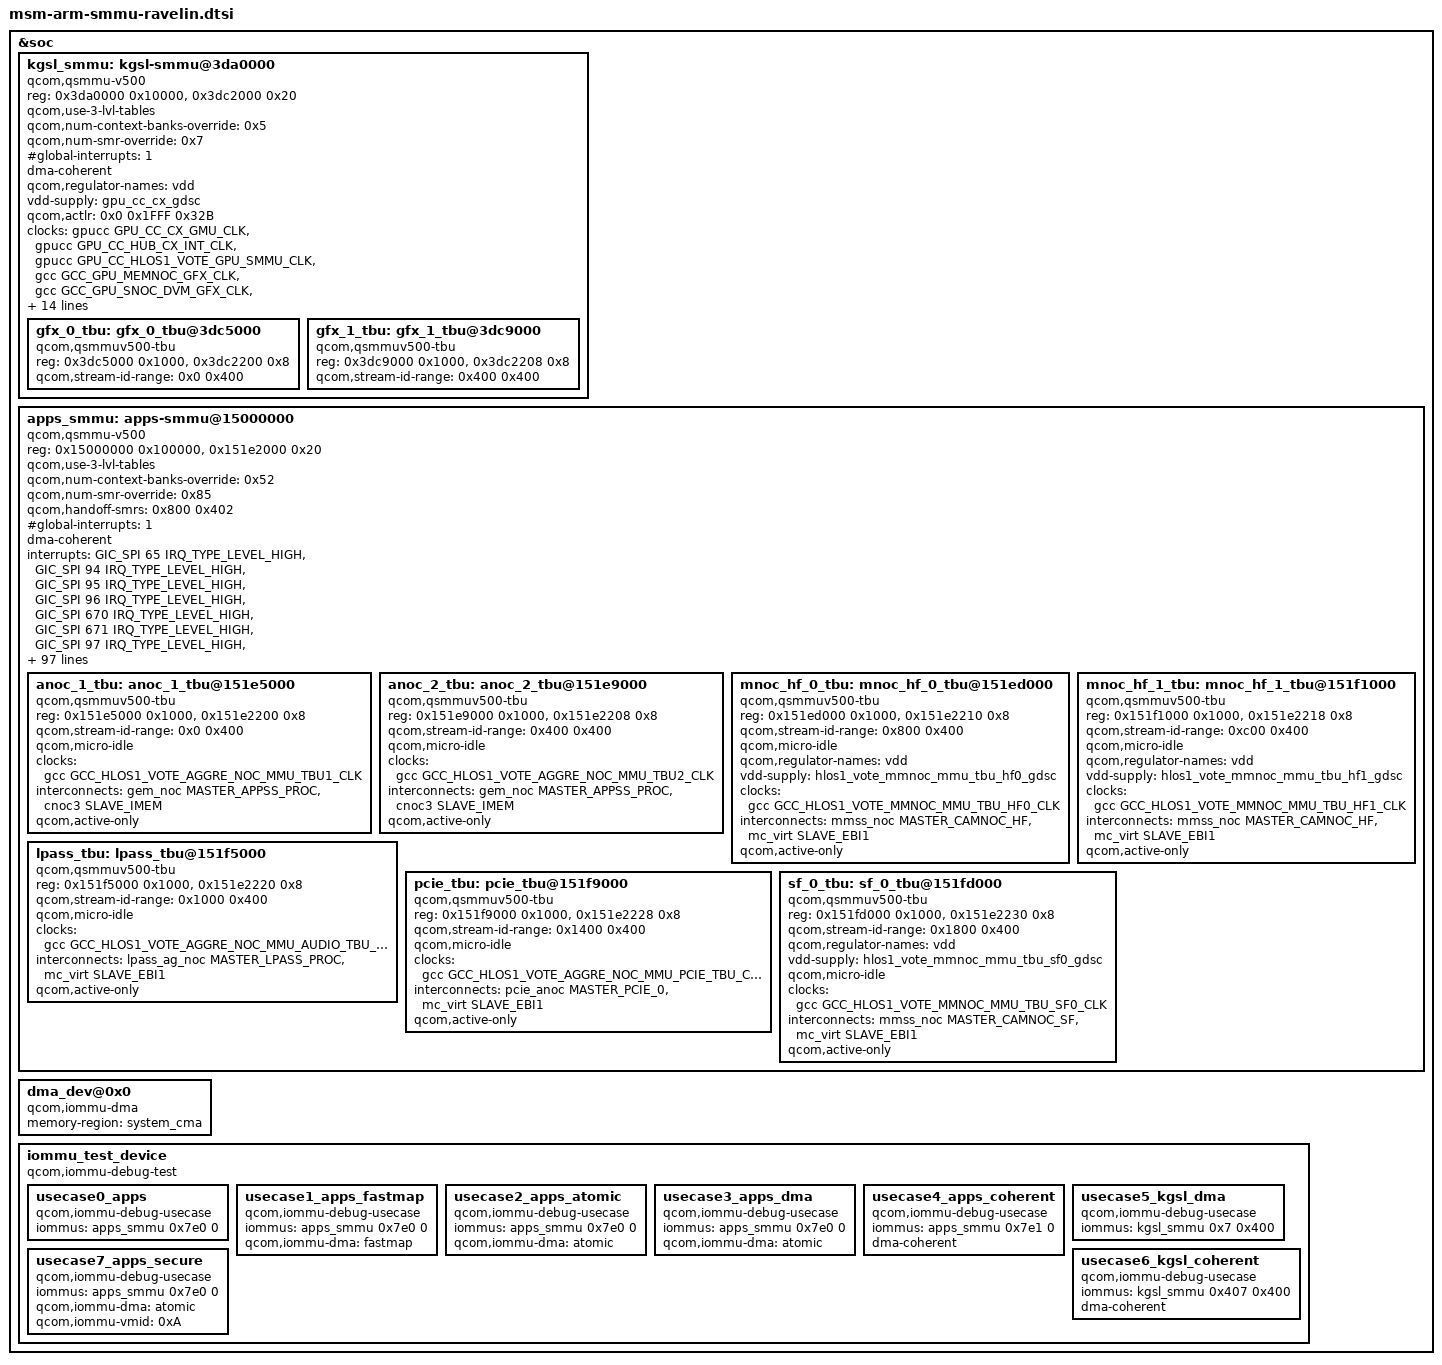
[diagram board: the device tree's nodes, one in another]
#include <dt-bindings/interrupt-controller/arm-gic.h>

&soc {
	kgsl_smmu: kgsl-smmu@3da0000 {
		compatible = "qcom,qsmmu-v500", "qcom,adreno-smmu";
		reg = <0x3da0000 0x10000>,
			<0x3dc2000 0x20>;
		reg-names = "base", "tcu-base";
		#iommu-cells = <2>;
		qcom,use-3-lvl-tables;
		qcom,num-context-banks-override = <0x5>;
		qcom,num-smr-override = <0x7>;
		#global-interrupts = <1>;
		#size-cells = <1>;
		#address-cells = <1>;
		ranges;
		dma-coherent;

		qcom,regulator-names = "vdd";
		vdd-supply = <&gpu_cc_cx_gdsc>;

		qcom,actlr =
			/* All CBs of GFX: +15 deep PF */
			<0x0 0x1FFF 0x32B>;

		clocks = <&gpucc GPU_CC_CX_GMU_CLK>,
			<&gpucc GPU_CC_HUB_CX_INT_CLK>,
			<&gpucc GPU_CC_HLOS1_VOTE_GPU_SMMU_CLK>,
			<&gcc GCC_GPU_MEMNOC_GFX_CLK>,
			<&gcc GCC_GPU_SNOC_DVM_GFX_CLK>,
			<&gpucc GPU_CC_AHB_CLK>;
		clock-names =
			"gpu_cc_cx_gmu",
			"gpu_cc_hub_cx_int",
			"gpu_cc_hlos1_vote_gpu_smmu",
			"gcc_gpu_memnoc_gfx",
			"gcc_gpu_snoc_dvm_gfx",
			"gpu_cc_ahb";

		interrupts =	<GIC_SPI 674 IRQ_TYPE_LEVEL_HIGH>,
				<GIC_SPI 678 IRQ_TYPE_LEVEL_HIGH>,
				<GIC_SPI 679 IRQ_TYPE_LEVEL_HIGH>,
				<GIC_SPI 680 IRQ_TYPE_LEVEL_HIGH>,
				<GIC_SPI 681 IRQ_TYPE_LEVEL_HIGH>,
				<GIC_SPI 682 IRQ_TYPE_LEVEL_HIGH>,
				<GIC_SPI 683 IRQ_TYPE_LEVEL_HIGH>,
				<GIC_SPI 684 IRQ_TYPE_LEVEL_HIGH>,
				<GIC_SPI 685 IRQ_TYPE_LEVEL_HIGH>,
				<GIC_SPI 686 IRQ_TYPE_LEVEL_HIGH>,
				<GIC_SPI 687 IRQ_TYPE_LEVEL_HIGH>,
				<GIC_SPI 688 IRQ_TYPE_LEVEL_HIGH>,
				<GIC_SPI 422 IRQ_TYPE_LEVEL_HIGH>;

		gfx_0_tbu: gfx_0_tbu@3dc5000 {
			compatible = "qcom,qsmmuv500-tbu";
			reg = <0x3dc5000 0x1000>,
				<0x3dc2200 0x8>;
			reg-names = "base", "status-reg";
			qcom,stream-id-range = <0x0 0x400>;
		};

		gfx_1_tbu: gfx_1_tbu@3dc9000 {
			compatible = "qcom,qsmmuv500-tbu";
			reg = <0x3dc9000 0x1000>,
				<0x3dc2208 0x8>;
			reg-names = "base", "status-reg";
			qcom,stream-id-range = <0x400 0x400>;
		};
	};

	apps_smmu: apps-smmu@15000000 {
		compatible = "qcom,qsmmu-v500";
		reg = <0x15000000 0x100000>,
			<0x151e2000 0x20>;
		reg-names = "base", "tcu-base";
		#iommu-cells = <2>;
		qcom,use-3-lvl-tables;
		qcom,num-context-banks-override = <0x52>;
		qcom,num-smr-override = <0x85>;
		qcom,handoff-smrs = <0x800 0x402>;
		#global-interrupts = <1>;
		#size-cells = <1>;
		#address-cells = <1>;
		ranges;
		dma-coherent;

		interrupts =	<GIC_SPI 65 IRQ_TYPE_LEVEL_HIGH>,
				<GIC_SPI 94 IRQ_TYPE_LEVEL_HIGH>,
				<GIC_SPI 95 IRQ_TYPE_LEVEL_HIGH>,
				<GIC_SPI 96 IRQ_TYPE_LEVEL_HIGH>,
				<GIC_SPI 670 IRQ_TYPE_LEVEL_HIGH>,
				<GIC_SPI 671 IRQ_TYPE_LEVEL_HIGH>,
				<GIC_SPI 97 IRQ_TYPE_LEVEL_HIGH>,
				<GIC_SPI 98 IRQ_TYPE_LEVEL_HIGH>,
				<GIC_SPI 99 IRQ_TYPE_LEVEL_HIGH>,
				<GIC_SPI 100 IRQ_TYPE_LEVEL_HIGH>,
				<GIC_SPI 101 IRQ_TYPE_LEVEL_HIGH>,
				<GIC_SPI 102 IRQ_TYPE_LEVEL_HIGH>,
				<GIC_SPI 103 IRQ_TYPE_LEVEL_HIGH>,
				<GIC_SPI 104 IRQ_TYPE_LEVEL_HIGH>,
				<GIC_SPI 105 IRQ_TYPE_LEVEL_HIGH>,
				<GIC_SPI 106 IRQ_TYPE_LEVEL_HIGH>,
				<GIC_SPI 107 IRQ_TYPE_LEVEL_HIGH>,
				<GIC_SPI 108 IRQ_TYPE_LEVEL_HIGH>,
				<GIC_SPI 109 IRQ_TYPE_LEVEL_HIGH>,
				<GIC_SPI 110 IRQ_TYPE_LEVEL_HIGH>,
				<GIC_SPI 111 IRQ_TYPE_LEVEL_HIGH>,
				<GIC_SPI 112 IRQ_TYPE_LEVEL_HIGH>,
				<GIC_SPI 113 IRQ_TYPE_LEVEL_HIGH>,
				<GIC_SPI 114 IRQ_TYPE_LEVEL_HIGH>,
				<GIC_SPI 115 IRQ_TYPE_LEVEL_HIGH>,
				<GIC_SPI 116 IRQ_TYPE_LEVEL_HIGH>,
				<GIC_SPI 117 IRQ_TYPE_LEVEL_HIGH>,
				<GIC_SPI 118 IRQ_TYPE_LEVEL_HIGH>,
				<GIC_SPI 181 IRQ_TYPE_LEVEL_HIGH>,
				<GIC_SPI 182 IRQ_TYPE_LEVEL_HIGH>,
				<GIC_SPI 183 IRQ_TYPE_LEVEL_HIGH>,
				<GIC_SPI 184 IRQ_TYPE_LEVEL_HIGH>,
				<GIC_SPI 185 IRQ_TYPE_LEVEL_HIGH>,
				<GIC_SPI 186 IRQ_TYPE_LEVEL_HIGH>,
				<GIC_SPI 187 IRQ_TYPE_LEVEL_HIGH>,
				<GIC_SPI 188 IRQ_TYPE_LEVEL_HIGH>,
				<GIC_SPI 189 IRQ_TYPE_LEVEL_HIGH>,
				<GIC_SPI 190 IRQ_TYPE_LEVEL_HIGH>,
				<GIC_SPI 191 IRQ_TYPE_LEVEL_HIGH>,
				<GIC_SPI 192 IRQ_TYPE_LEVEL_HIGH>,
				<GIC_SPI 315 IRQ_TYPE_LEVEL_HIGH>,
				<GIC_SPI 316 IRQ_TYPE_LEVEL_HIGH>,
				<GIC_SPI 317 IRQ_TYPE_LEVEL_HIGH>,
				<GIC_SPI 318 IRQ_TYPE_LEVEL_HIGH>,
				<GIC_SPI 319 IRQ_TYPE_LEVEL_HIGH>,
				<GIC_SPI 320 IRQ_TYPE_LEVEL_HIGH>,
				<GIC_SPI 321 IRQ_TYPE_LEVEL_HIGH>,
				<GIC_SPI 322 IRQ_TYPE_LEVEL_HIGH>,
				<GIC_SPI 323 IRQ_TYPE_LEVEL_HIGH>,
				<GIC_SPI 324 IRQ_TYPE_LEVEL_HIGH>,
				<GIC_SPI 325 IRQ_TYPE_LEVEL_HIGH>,
				<GIC_SPI 326 IRQ_TYPE_LEVEL_HIGH>,
				<GIC_SPI 327 IRQ_TYPE_LEVEL_HIGH>,
				<GIC_SPI 328 IRQ_TYPE_LEVEL_HIGH>,
				<GIC_SPI 329 IRQ_TYPE_LEVEL_HIGH>,
				<GIC_SPI 330 IRQ_TYPE_LEVEL_HIGH>,
				<GIC_SPI 331 IRQ_TYPE_LEVEL_HIGH>,
				<GIC_SPI 332 IRQ_TYPE_LEVEL_HIGH>,
				<GIC_SPI 333 IRQ_TYPE_LEVEL_HIGH>,
				<GIC_SPI 334 IRQ_TYPE_LEVEL_HIGH>,
				<GIC_SPI 335 IRQ_TYPE_LEVEL_HIGH>,
				<GIC_SPI 336 IRQ_TYPE_LEVEL_HIGH>,
				<GIC_SPI 337 IRQ_TYPE_LEVEL_HIGH>,
				<GIC_SPI 338 IRQ_TYPE_LEVEL_HIGH>,
				<GIC_SPI 339 IRQ_TYPE_LEVEL_HIGH>,
				<GIC_SPI 340 IRQ_TYPE_LEVEL_HIGH>,
				<GIC_SPI 341 IRQ_TYPE_LEVEL_HIGH>,
				<GIC_SPI 342 IRQ_TYPE_LEVEL_HIGH>,
				<GIC_SPI 343 IRQ_TYPE_LEVEL_HIGH>,
				<GIC_SPI 344 IRQ_TYPE_LEVEL_HIGH>,
				<GIC_SPI 345 IRQ_TYPE_LEVEL_HIGH>,
				<GIC_SPI 395 IRQ_TYPE_LEVEL_HIGH>,
				<GIC_SPI 396 IRQ_TYPE_LEVEL_HIGH>,
				<GIC_SPI 397 IRQ_TYPE_LEVEL_HIGH>,
				<GIC_SPI 398 IRQ_TYPE_LEVEL_HIGH>,
				<GIC_SPI 399 IRQ_TYPE_LEVEL_HIGH>,
				<GIC_SPI 400 IRQ_TYPE_LEVEL_HIGH>,
				<GIC_SPI 401 IRQ_TYPE_LEVEL_HIGH>,
				<GIC_SPI 402 IRQ_TYPE_LEVEL_HIGH>,
				<GIC_SPI 403 IRQ_TYPE_LEVEL_HIGH>,
				<GIC_SPI 404 IRQ_TYPE_LEVEL_HIGH>,
				<GIC_SPI 405 IRQ_TYPE_LEVEL_HIGH>,
				<GIC_SPI 406 IRQ_TYPE_LEVEL_HIGH>,
				<GIC_SPI 407 IRQ_TYPE_LEVEL_HIGH>,
				<GIC_SPI 408 IRQ_TYPE_LEVEL_HIGH>,
				<GIC_SPI 409 IRQ_TYPE_LEVEL_HIGH>,
				<GIC_SPI 418 IRQ_TYPE_LEVEL_HIGH>,
				<GIC_SPI 419 IRQ_TYPE_LEVEL_HIGH>,
				<GIC_SPI 412 IRQ_TYPE_LEVEL_HIGH>,
				<GIC_SPI 421 IRQ_TYPE_LEVEL_HIGH>,
				<GIC_SPI 707 IRQ_TYPE_LEVEL_HIGH>,
				<GIC_SPI 423 IRQ_TYPE_LEVEL_HIGH>,
				<GIC_SPI 424 IRQ_TYPE_LEVEL_HIGH>,
				<GIC_SPI 425 IRQ_TYPE_LEVEL_HIGH>,
				<GIC_SPI 690 IRQ_TYPE_LEVEL_HIGH>,
				<GIC_SPI 691 IRQ_TYPE_LEVEL_HIGH>,
				<GIC_SPI 692 IRQ_TYPE_LEVEL_HIGH>;

		qcom,actlr =
			/* For video clients, +3 PF */
			<0x1980 0x3F 0x103>,
			/* Display and camera clients, +0 PF */
			<0x1900 0x3F 0x1>,
			<0x1800 0xFF 0x1>,
			<0x800 0x7FF 0x1>;

		clocks = <&gcc GCC_HLOS1_VOTE_MMU_TCU_CLK>;
		clock-names =
			"gcc_hlos1_vote_mmu_tcu_clk";
		interconnects = <&gem_noc MASTER_APPSS_PROC
				&cnoc3 SLAVE_TCU>;
		qcom,active-only;

		anoc_1_tbu: anoc_1_tbu@151e5000 {
			compatible = "qcom,qsmmuv500-tbu";
			reg = <0x151e5000 0x1000>,
				<0x151e2200 0x8>;
			reg-names = "base", "status-reg";
			qcom,stream-id-range = <0x0 0x400>;
			qcom,micro-idle;
			clocks = <&gcc GCC_HLOS1_VOTE_AGGRE_NOC_MMU_TBU1_CLK>;
			clock-names =
				"gcc_hlos1_vote_aggre_noc_mmu_tbu1_clk";
			interconnects = <&gem_noc MASTER_APPSS_PROC
					&cnoc3 SLAVE_IMEM>;
			qcom,active-only;
		};

		anoc_2_tbu: anoc_2_tbu@151e9000 {
			compatible = "qcom,qsmmuv500-tbu";
			reg = <0x151e9000 0x1000>,
				<0x151e2208  0x8>;
			reg-names = "base", "status-reg";
			qcom,stream-id-range = <0x400 0x400>;
			qcom,micro-idle;
			clocks = <&gcc GCC_HLOS1_VOTE_AGGRE_NOC_MMU_TBU2_CLK>;
			clock-names =
				"gcc_hlos1_vote_aggre_noc_mmu_tbu2_clk";
			interconnects = <&gem_noc MASTER_APPSS_PROC
					&cnoc3 SLAVE_IMEM>;
			qcom,active-only;
		};

		mnoc_hf_0_tbu: mnoc_hf_0_tbu@151ed000 {
			compatible = "qcom,qsmmuv500-tbu";
			reg = <0x151ed000 0x1000>,
				<0x151e2210  0x8>;
			reg-names = "base", "status-reg";
			qcom,stream-id-range = <0x800 0x400>;
			qcom,micro-idle;
			qcom,regulator-names = "vdd";
			vdd-supply = <&hlos1_vote_mmnoc_mmu_tbu_hf0_gdsc>;
			clocks = <&gcc GCC_HLOS1_VOTE_MMNOC_MMU_TBU_HF0_CLK>;
			clock-names =
				"gcc_hlos1_vote_mmnoc_mmu_tbu_hf0_clk";
			interconnects = <&mmss_noc MASTER_CAMNOC_HF
					&mc_virt SLAVE_EBI1>;
			qcom,active-only;
		};

		mnoc_hf_1_tbu: mnoc_hf_1_tbu@151f1000 {
			compatible = "qcom,qsmmuv500-tbu";
			reg = <0x151f1000 0x1000>,
				<0x151e2218  0x8>;
			reg-names = "base", "status-reg";
			qcom,stream-id-range = <0xc00 0x400>;
			qcom,micro-idle;
			qcom,regulator-names = "vdd";
			vdd-supply = <&hlos1_vote_mmnoc_mmu_tbu_hf1_gdsc>;
			clocks = <&gcc GCC_HLOS1_VOTE_MMNOC_MMU_TBU_HF1_CLK>;
			clock-names =
				"gcc_hlos1_vote_mmnoc_mmu_tbu_hf1_clk";
			interconnects = <&mmss_noc MASTER_CAMNOC_HF
					&mc_virt SLAVE_EBI1>;
			qcom,active-only;
		};

		lpass_tbu: lpass_tbu@151f5000 {
			compatible = "qcom,qsmmuv500-tbu";
			reg = <0x151f5000 0x1000>,
				<0x151e2220  0x8>;
			reg-names = "base", "status-reg";
			qcom,stream-id-range = <0x1000 0x400>;
			qcom,micro-idle;
			clocks = <&gcc GCC_HLOS1_VOTE_AGGRE_NOC_MMU_AUDIO_TBU_CLK>;
			clock-names =
				"gcc_hlos1_vote_aggre_noc_mmu_audio_tbu_clk";
			interconnects = <&lpass_ag_noc MASTER_LPASS_PROC
					&mc_virt SLAVE_EBI1>;
			qcom,active-only;
		};

		pcie_tbu: pcie_tbu@151f9000 {
			compatible = "qcom,qsmmuv500-tbu";
			reg = <0x151f9000 0x1000>,
				<0x151e2228  0x8>;
			reg-names = "base", "status-reg";
			qcom,stream-id-range = <0x1400 0x400>;
			qcom,micro-idle;
			clocks = <&gcc GCC_HLOS1_VOTE_AGGRE_NOC_MMU_PCIE_TBU_CLK>;
			clock-names =
				"gcc_hlos1_vote_aggre_noc_mmu_pcie_tbu_clk";
			interconnects = <&pcie_anoc MASTER_PCIE_0
					&mc_virt SLAVE_EBI1>;
			qcom,active-only;
		};

		sf_0_tbu: sf_0_tbu@151fd000 {
			compatible = "qcom,qsmmuv500-tbu";
			reg = <0x151fd000 0x1000>,
				<0x151e2230  0x8>;
			reg-names = "base", "status-reg";
			qcom,stream-id-range = <0x1800 0x400>;
			qcom,regulator-names = "vdd";
			vdd-supply = <&hlos1_vote_mmnoc_mmu_tbu_sf0_gdsc>;
			qcom,micro-idle;
			clocks = <&gcc GCC_HLOS1_VOTE_MMNOC_MMU_TBU_SF0_CLK>;
			clock-names =
				"gcc_hlos1_vote_mmnoc_mmu_tbu_sf0_clk";
			interconnects = <&mmss_noc MASTER_CAMNOC_SF
					&mc_virt SLAVE_EBI1>;
			qcom,active-only;
		};
	};

	dma_dev@0x0 {
		compatible = "qcom,iommu-dma";
		memory-region = <&system_cma>;
	};

	iommu_test_device {
		compatible = "qcom,iommu-debug-test";

		usecase0_apps {
			compatible = "qcom,iommu-debug-usecase";
			iommus = <&apps_smmu 0x7e0 0>;
		};

		usecase1_apps_fastmap {
			compatible = "qcom,iommu-debug-usecase";
			iommus = <&apps_smmu 0x7e0 0>;
			qcom,iommu-dma = "fastmap";
		};

		usecase2_apps_atomic {
			compatible = "qcom,iommu-debug-usecase";
			iommus = <&apps_smmu 0x7e0 0>;
			qcom,iommu-dma = "atomic";
		};

		usecase3_apps_dma {
			compatible = "qcom,iommu-debug-usecase";
			iommus = <&apps_smmu 0x7e0 0>;
			qcom,iommu-dma = "atomic";
		};

		usecase4_apps_coherent {
			compatible = "qcom,iommu-debug-usecase";
			iommus = <&apps_smmu 0x7e1 0>;
			dma-coherent;
		};

		usecase5_kgsl_dma {
			compatible = "qcom,iommu-debug-usecase";
			iommus = <&kgsl_smmu 0x7 0x400>;
		};

		usecase6_kgsl_coherent {
			compatible = "qcom,iommu-debug-usecase";
			iommus = <&kgsl_smmu 0x407 0x400>;
			dma-coherent;
		};

		usecase7_apps_secure {
			compatible = "qcom,iommu-debug-usecase";
			iommus = <&apps_smmu 0x7e0 0>;
			qcom,iommu-dma = "atomic";
			qcom,iommu-vmid = <0xA>; /* VMID_CP_PIXEL */
		};
	};
};
